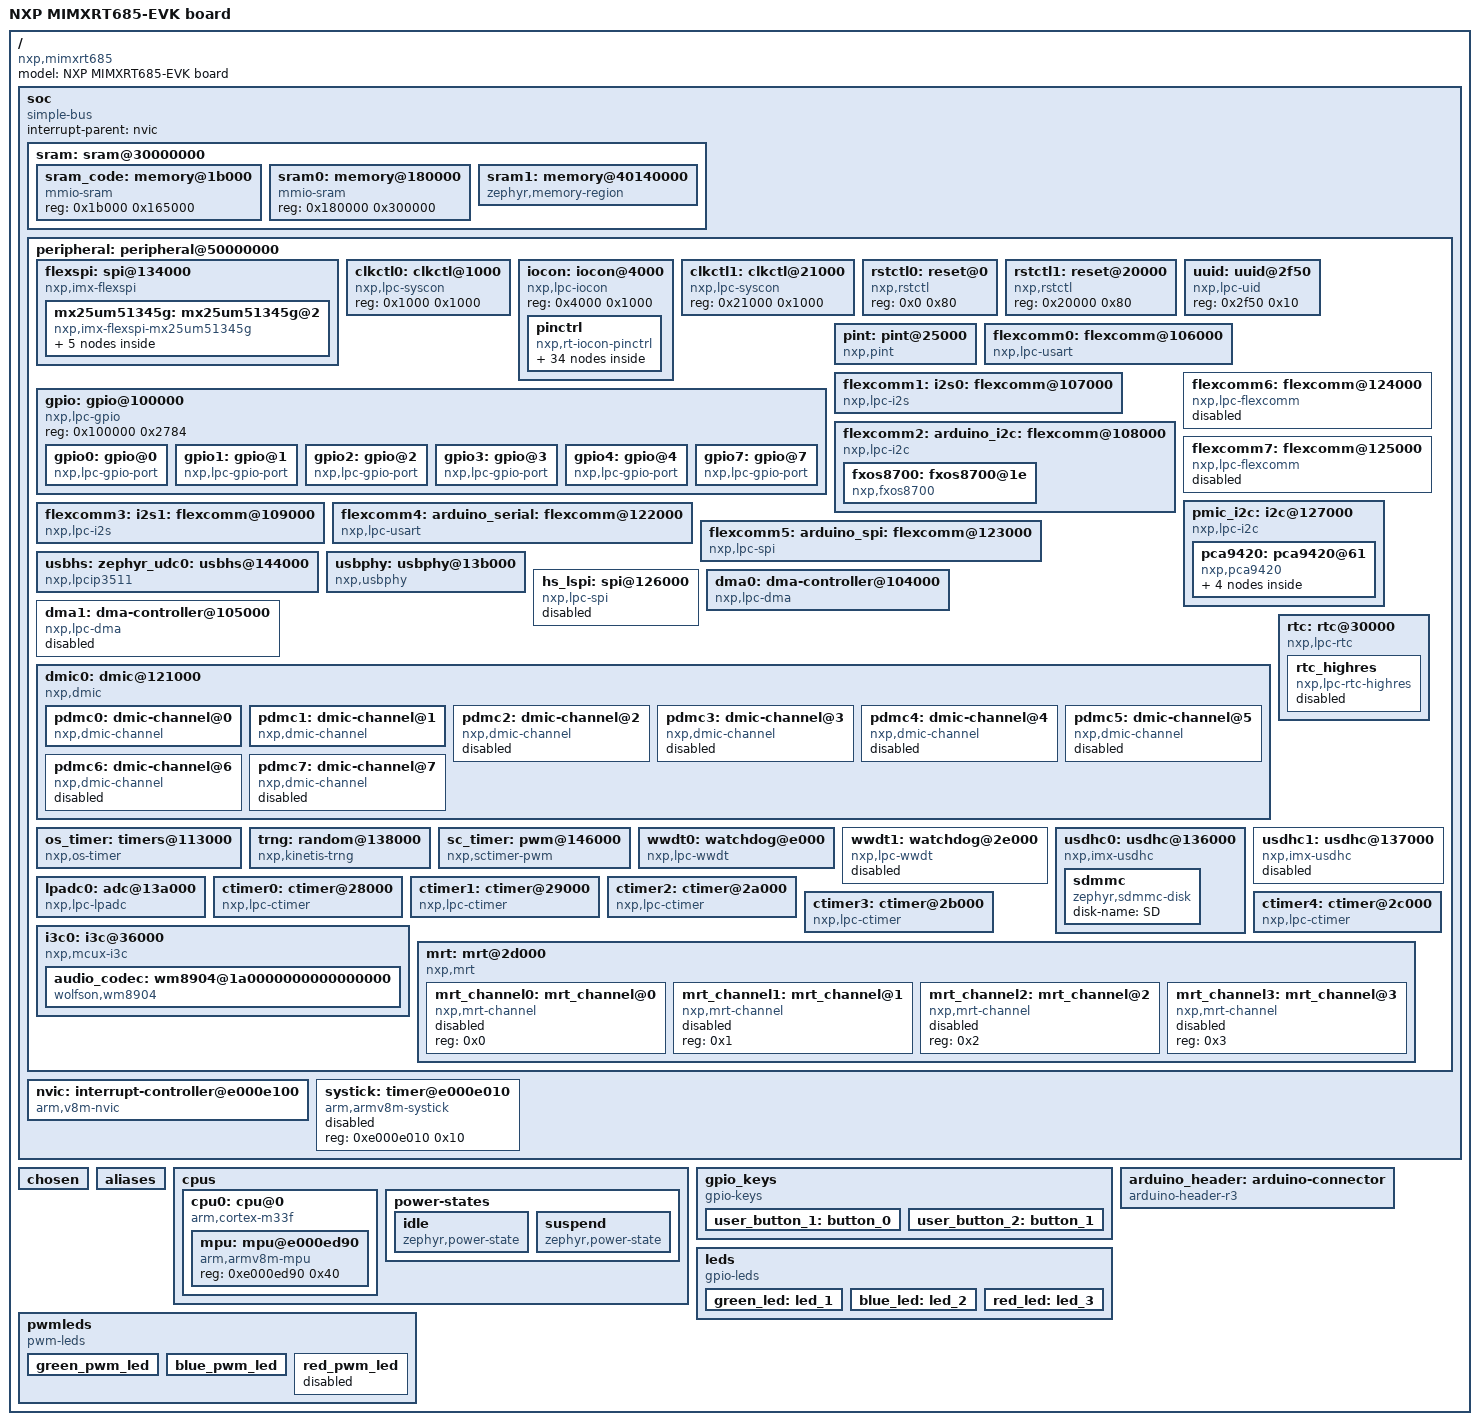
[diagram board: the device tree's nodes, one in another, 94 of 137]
/dts-v1/;

/ {
	#address-cells = < 0x1 >;
	#size-cells = < 0x1 >;
	model = "NXP MIMXRT685-EVK board";
	compatible = "nxp,mimxrt685";
	soc {
		#address-cells = < 0x1 >;
		#size-cells = < 0x1 >;
		compatible = "simple-bus";
		interrupt-parent = < &nvic >;
		ranges;
		sram: sram@30000000 {
			ranges = < 0x20000000 0x30000000 0x500000 0x0 0x10000000 0x500000 >;
			#address-cells = < 0x1 >;
			#size-cells = < 0x1 >;
			sram_code: memory@1b000 {
				compatible = "mmio-sram";
				reg = < 0x1b000 0x165000 >;
			};
			sram0: memory@180000 {
				compatible = "mmio-sram";
				reg = < 0x180000 0x300000 >;
			};
			sram1: memory@40140000 {
				compatible = "zephyr,memory-region", "mmio-sram";
				reg = < 0x40140000 0x4000 >;
				zephyr,memory-region = "SRAM1";
				zephyr,memory-attr = < 0x100000 >;
				status = "okay";
			};
		};
		peripheral: peripheral@50000000 {
			ranges = < 0x0 0x50000000 0x10000000 >;
			#address-cells = < 0x1 >;
			#size-cells = < 0x1 >;
			flexspi: spi@134000 {
				reg = < 0x134000 0x1000 >, < 0x18000000 0x8000000 >;
				compatible = "nxp,imx-flexspi";
				interrupts = < 0x2a 0x0 >;
				#address-cells = < 0x1 >;
				#size-cells = < 0x0 >;
				status = "okay";
				clocks = < &clkctl1 0xa00 >;
				pinctrl-0 = < &pinmux_flexspi >;
				pinctrl-names = "default";
				mx25um51345g: mx25um51345g@2 {
					compatible = "nxp,imx-flexspi-mx25um51345g";
					size = < 0x20000000 >;
					reg = < 0x2 >;
					spi-max-frequency = < 0xbebc200 >;
					status = "okay";
					jedec-id = [ C2 81 3A ];
					erase-block-size = < 0x1000 >;
					write-block-size = < 0x1 >;
					partitions {
						compatible = "fixed-partitions";
						#address-cells = < 0x1 >;
						#size-cells = < 0x1 >;
						boot_partition: partition@0 {
							label = "mcuboot";
							reg = < 0x0 0x20000 >;
						};
						slot0_partition: partition@20000 {
							label = "image-0";
							reg = < 0x20000 0x302000 >;
						};
						slot1_partition: partition@323000 {
							label = "image-1";
							reg = < 0x323000 0x300000 >;
						};
						storage_partition: partition@623000 {
							label = "storage";
							reg = < 0x623000 0x39de000 >;
						};
					};
				};
			};
			clkctl0: clkctl@1000 {
				compatible = "nxp,lpc-syscon";
				reg = < 0x1000 0x1000 >;
				#clock-cells = < 0x1 >;
				phandle = < 0xf >;
			};
			iocon: iocon@4000 {
				compatible = "nxp,lpc-iocon";
				reg = < 0x4000 0x1000 >;
				pinctrl: pinctrl {
					compatible = "nxp,rt-iocon-pinctrl";
					pinmux_flexcomm0_usart: pinmux_flexcomm0_usart {
						phandle = < 0x5 >;
						group0 {
							pinmux = < 0x200001 >;
							input-enable;
							slew-rate = "normal";
							drive-strength = "normal";
						};
						group1 {
							pinmux = < 0x100001 >;
							slew-rate = "normal";
							drive-strength = "normal";
							input-enable;
						};
					};
					pinmux_flexcomm1_i2s: pinmux_flexcomm1_i2s {
						phandle = < 0x7 >;
						group0 {
							pinmux = < 0x900001 >;
							input-enable;
							slew-rate = "normal";
							drive-strength = "high";
						};
					};
					pinmux_flexcomm2_i2c: pinmux_flexcomm2_i2c {
						phandle = < 0x8 >;
						group0 {
							pinmux = < 0x1100001 >, < 0x1200001 >;
							bias-pull-up;
							input-enable;
							slew-rate = "normal";
							drive-strength = "high";
							drive-open-drain;
						};
					};
					pinmux_flexcomm3_i2s: pinmux_flexcomm3_i2s {
						phandle = < 0xa >;
						group0 {
							pinmux = < 0x1700001 >, < 0x1600001 >, < 0x1500001 >, < 0x2a00001 >;
							input-enable;
							slew-rate = "normal";
							drive-strength = "high";
						};
					};
					pinmux_flexcomm4_usart: pinmux_flexcomm4_usart {
						phandle = < 0xb >;
						group0 {
							pinmux = < 0x1e00001 >;
							input-enable;
							slew-rate = "normal";
							drive-strength = "normal";
						};
						group1 {
							pinmux = < 0x1d00001 >;
							slew-rate = "normal";
							drive-strength = "normal";
						};
					};
					pinmux_flexcomm5_spi: pinmux_flexcomm5_spi {
						phandle = < 0xc >;
						group0 {
							pinmux = < 0x2300001 >, < 0x2400001 >, < 0x2500001 >, < 0x2600001 >;
							input-enable;
							slew-rate = "normal";
							drive-strength = "normal";
						};
					};
					pinmux_dmic0: pinmux_dmic0 {
						phandle = < 0x10 >;
						group0 {
							pinmux = < 0x5500001 >, < 0x5400001 >, < 0x5000001 >;
							slew-rate = "normal";
							drive-strength = "normal";
							input-enable;
						};
					};
					pinmux_flexspi: pinmux_flexspi {
						phandle = < 0x3 >;
						group0 {
							pinmux = < 0x2b00006 >, < 0x2c00006 >, < 0x2d00006 >, < 0x2e00006 >, < 0x3d00005 >, < 0x5100006 >, < 0x5200006 >, < 0x5300006 >, < 0x5600006 >, < 0x5700006 >;
							input-enable;
							slew-rate = "normal";
							drive-strength = "high";
						};
						group1 {
							pinmux = < 0x4c00000 >;
							slew-rate = "normal";
							drive-strength = "normal";
						};
					};
					pinmux_lpadc0: pinmux_lpadc0 {
						phandle = < 0x14 >;
						group0 {
							pinmux = < 0x500000 >, < 0x600000 >;
							slew-rate = "normal";
							drive-strength = "normal";
							nxp,analog-mode;
						};
					};
					pinmux_pmic_i2c: pinmux_pmic_i2c {
						phandle = < 0xd >;
						group0 {
							pinmux = < 0x10000000 >, < 0x10100000 >;
							bias-pull-up;
							input-enable;
							slew-rate = "normal";
							drive-strength = "normal";
							drive-open-drain;
						};
					};
					pinmux_sctimer: pinmux_sctimer {
						phandle = < 0x11 >;
						group0 {
							pinmux = < 0x1b00003 >, < 0xe00003 >, < 0x1a00003 >, < 0x1f00003 >;
							slew-rate = "normal";
							drive-strength = "normal";
						};
					};
					pinmux_usdhc: pinmux_usdhc {
						phandle = < 0x13 >;
						group0 {
							pinmux = < 0x3f00001 >, < 0x4000001 >, < 0x4100001 >, < 0x4200001 >, < 0x4300001 >, < 0x4900000 >;
							bias-pull-up;
							input-enable;
							slew-rate = "normal";
							drive-strength = "normal";
						};
						group1 {
							pinmux = < 0x3e00001 >;
							input-enable;
							slew-rate = "normal";
							drive-strength = "normal";
						};
						group2 {
							pinmux = < 0x4a00000 >, < 0x4400000 >;
							slew-rate = "normal";
							drive-strength = "normal";
						};
					};
					pinmux_i3c: pinmux_i3c {
						phandle = < 0x15 >;
						group0 {
							pinmux = < 0x5d00001 >, < 0x5e00001 >;
							input-enable;
							slew-rate = "slow";
							drive-strength = "high";
						};
						group1 {
							pinmux = < 0x5f00001 >;
							slew-rate = "normal";
							drive-strength = "normal";
						};
					};
					pinmux_ctimer2_pwm: pinmux_ctimer2_pwm {
						group0 {
							pinmux = < 0xe00004 >;
							slew-rate = "normal";
							drive-strength = "normal";
						};
					};
				};
			};
			clkctl1: clkctl@21000 {
				compatible = "nxp,lpc-syscon";
				reg = < 0x21000 0x1000 >;
				#clock-cells = < 0x1 >;
				phandle = < 0x2 >;
			};
			rstctl0: reset@0 {
				compatible = "nxp,rstctl";
				reg = < 0x0 0x80 >;
				#reset-cells = < 0x1 >;
			};
			rstctl1: reset@20000 {
				compatible = "nxp,rstctl";
				reg = < 0x20000 0x80 >;
				#reset-cells = < 0x1 >;
				phandle = < 0x4 >;
			};
			uuid: uuid@2f50 {
				compatible = "nxp,lpc-uid";
				reg = < 0x2f50 0x10 >;
			};
			gpio: gpio@100000 {
				compatible = "nxp,lpc-gpio";
				reg = < 0x100000 0x2784 >;
				#address-cells = < 0x1 >;
				#size-cells = < 0x0 >;
				gpio0: gpio@0 {
					compatible = "nxp,lpc-gpio-port";
					int-source = "pint";
					gpio-controller;
					#gpio-cells = < 0x2 >;
					reg = < 0x0 >;
					status = "okay";
					phandle = < 0x18 >;
				};
				gpio1: gpio@1 {
					compatible = "nxp,lpc-gpio-port";
					int-source = "pint";
					gpio-controller;
					#gpio-cells = < 0x2 >;
					reg = < 0x1 >;
					status = "okay";
					phandle = < 0x9 >;
				};
				gpio2: gpio@2 {
					compatible = "nxp,lpc-gpio-port";
					gpio-controller;
					#gpio-cells = < 0x2 >;
					reg = < 0x2 >;
					status = "okay";
					phandle = < 0x12 >;
				};
				gpio3: gpio@3 {
					compatible = "nxp,lpc-gpio-port";
					gpio-controller;
					#gpio-cells = < 0x2 >;
					reg = < 0x3 >;
				};
				gpio4: gpio@4 {
					compatible = "nxp,lpc-gpio-port";
					gpio-controller;
					#gpio-cells = < 0x2 >;
					reg = < 0x4 >;
				};
				gpio7: gpio@7 {
					compatible = "nxp,lpc-gpio-port";
					gpio-controller;
					#gpio-cells = < 0x2 >;
					reg = < 0x7 >;
				};
			};
			pint: pint@25000 {
				compatible = "nxp,pint";
				reg = < 0x25000 0x1000 >;
				interrupt-controller;
				#interrupt-cells = < 0x1 >;
				#address-cells = < 0x0 >;
				interrupts = < 0x4 0x2 >, < 0x5 0x2 >, < 0x6 0x2 >, < 0x7 0x2 >, < 0x23 0x2 >, < 0x24 0x2 >, < 0x25 0x2 >, < 0x26 0x2 >;
				num-lines = < 0x8 >;
				num-inputs = < 0x40 >;
			};
			flexcomm0: flexcomm@106000 {
				compatible = "nxp,lpc-usart";
				reg = < 0x106000 0x1000 >;
				interrupts = < 0xe 0x0 >;
				clocks = < &clkctl1 0x100 >;
				resets = < &rstctl1 0x8 >;
				status = "okay";
				current-speed = < 0x1c200 >;
				pinctrl-0 = < &pinmux_flexcomm0_usart >;
				pinctrl-names = "default";
				dmas = < &dma0 0x0 >, < &dma0 0x1 >;
				dma-names = "rx", "tx";
			};
			flexcomm1: i2s0: flexcomm@107000 {
				compatible = "nxp,lpc-i2s";
				reg = < 0x107000 0x1000 >;
				interrupts = < 0xf 0x0 >;
				clocks = < &clkctl1 0x101 >;
				resets = < &rstctl1 0x9 >;
				status = "okay";
				#address-cells = < 0x1 >;
				#size-cells = < 0x0 >;
				dmas = < &dma0 0x2 >;
				dma-names = "rx";
				pinctrl-0 = < &pinmux_flexcomm1_i2s >;
				pinctrl-names = "default";
			};
			flexcomm2: arduino_i2c: flexcomm@108000 {
				compatible = "nxp,lpc-i2c";
				reg = < 0x108000 0x1000 >;
				interrupts = < 0x10 0x0 >;
				clocks = < &clkctl1 0x102 >;
				resets = < &rstctl1 0xa >;
				status = "okay";
				pinctrl-0 = < &pinmux_flexcomm2_i2c >;
				pinctrl-names = "default";
				clock-frequency = < 0x61a80 >;
				#address-cells = < 0x1 >;
				#size-cells = < 0x0 >;
				fxos8700: fxos8700@1e {
					compatible = "nxp,fxos8700";
					reg = < 0x1e >;
					int1-gpios = < &gpio1 0x5 0x1 >;
					reset-gpios = < &gpio1 0x7 0x0 >;
				};
			};
			flexcomm3: i2s1: flexcomm@109000 {
				compatible = "nxp,lpc-i2s";
				reg = < 0x109000 0x1000 >;
				interrupts = < 0x11 0x0 >;
				clocks = < &clkctl1 0x103 >;
				resets = < &rstctl1 0xb >;
				status = "okay";
				#address-cells = < 0x1 >;
				#size-cells = < 0x0 >;
				dmas = < &dma0 0x7 >;
				dma-names = "tx";
				pinctrl-0 = < &pinmux_flexcomm3_i2s >;
				pinctrl-names = "default";
			};
			flexcomm4: arduino_serial: flexcomm@122000 {
				compatible = "nxp,lpc-usart";
				reg = < 0x122000 0x1000 >;
				interrupts = < 0x12 0x0 >;
				clocks = < &clkctl1 0x104 >;
				resets = < &rstctl1 0xc >;
				status = "okay";
				current-speed = < 0x1c200 >;
				pinctrl-0 = < &pinmux_flexcomm4_usart >;
				pinctrl-names = "default";
				dmas = < &dma0 0x8 >, < &dma0 0x9 >;
				dma-names = "rx", "tx";
			};
			flexcomm5: arduino_spi: flexcomm@123000 {
				compatible = "nxp,lpc-spi";
				reg = < 0x123000 0x1000 >;
				interrupts = < 0x13 0x0 >;
				clocks = < &clkctl1 0x105 >;
				resets = < &rstctl1 0xd >;
				status = "okay";
				#address-cells = < 0x1 >;
				#size-cells = < 0x0 >;
				dmas = < &dma0 0xa >, < &dma0 0xb >;
				dma-names = "rx", "tx";
				pinctrl-0 = < &pinmux_flexcomm5_spi >;
				pinctrl-names = "default";
			};
			flexcomm6: flexcomm@124000 {
				compatible = "nxp,lpc-flexcomm";
				reg = < 0x124000 0x1000 >;
				interrupts = < 0x2b 0x0 >;
				clocks = < &clkctl1 0x106 >;
				resets = < &rstctl1 0xe >;
				status = "disabled";
			};
			flexcomm7: flexcomm@125000 {
				compatible = "nxp,lpc-flexcomm";
				reg = < 0x125000 0x1000 >;
				interrupts = < 0x2c 0x0 >;
				clocks = < &clkctl1 0x107 >;
				resets = < &rstctl1 0xf >;
				status = "disabled";
			};
			pmic_i2c: i2c@127000 {
				compatible = "nxp,lpc-i2c";
				reg = < 0x127000 0x1000 >;
				interrupts = < 0x15 0x0 >;
				clocks = < &clkctl1 0x10f >;
				resets = < &rstctl1 0x17 >;
				status = "okay";
				clock-frequency = < 0x61a80 >;
				#address-cells = < 0x1 >;
				#size-cells = < 0x0 >;
				pinctrl-0 = < &pinmux_pmic_i2c >;
				pinctrl-names = "default";
				pca9420: pca9420@61 {
					compatible = "nxp,pca9420";
					reg = < 0x61 >;
					nxp,enable-modesel-pins;
					buck1: BUCK1 {
						regulator-boot-on;
					};
					buck2: BUCK2 {
						regulator-boot-on;
					};
					ldo1: LDO1 {
						regulator-boot-on;
					};
					ldo2: LDO2 {
						regulator-boot-on;
					};
				};
			};
			usbhs: zephyr_udc0: usbhs@144000 {
				compatible = "nxp,lpcip3511";
				reg = < 0x144000 0x1000 >;
				interrupts = < 0x32 0x1 >;
				num-bidir-endpoints = < 0x6 >;
				status = "okay";
				phy_handle = < &usbphy >;
			};
			usbphy: usbphy@13b000 {
				compatible = "nxp,usbphy";
				reg = < 0x13b000 0x1000 >;
				status = "okay";
				tx-d-cal = < 0xc >;
				tx-cal-45-dp-ohms = < 0x6 >;
				tx-cal-45-dm-ohms = < 0x6 >;
				phandle = < 0xe >;
			};
			hs_lspi: spi@126000 {
				compatible = "nxp,lpc-spi";
				reg = < 0x126000 0x1000 >;
				interrupts = < 0x14 0x0 >;
				clocks = < &clkctl1 0x10e >;
				resets = < &rstctl1 0x16 >;
				status = "disabled";
				#address-cells = < 0x1 >;
				#size-cells = < 0x0 >;
			};
			dma0: dma-controller@104000 {
				compatible = "nxp,lpc-dma";
				reg = < 0x104000 0x1000 >;
				interrupts = < 0x1 0x0 >;
				dma-channels = < 0x21 >;
				status = "okay";
				#dma-cells = < 0x1 >;
				phandle = < 0x6 >;
			};
			dma1: dma-controller@105000 {
				compatible = "nxp,lpc-dma";
				reg = < 0x105000 0x1000 >;
				interrupts = < 0x36 0x0 >;
				dma-channels = < 0x21 >;
				status = "disabled";
				#dma-cells = < 0x1 >;
			};
			dmic0: dmic@121000 {
				#address-cells = < 0x1 >;
				#size-cells = < 0x0 >;
				compatible = "nxp,dmic";
				reg = < 0x121000 0x1000 >;
				interrupts = < 0x19 0x0 >;
				status = "okay";
				clocks = < &clkctl0 0xa00 >;
				pinctrl-0 = < &pinmux_dmic0 >;
				pinctrl-names = "default";
				use2fs;
				pdmc0: dmic-channel@0 {
					compatible = "nxp,dmic-channel";
					reg = < 0x0 >;
					dmas = < &dma0 0x10 >;
					status = "okay";
					gainshift = < 0x3 >;
					dc-cutoff = "155hz";
					dc-gain = < 0x1 >;
				};
				pdmc1: dmic-channel@1 {
					compatible = "nxp,dmic-channel";
					reg = < 0x1 >;
					dmas = < &dma0 0x11 >;
					status = "okay";
					gainshift = < 0x3 >;
					dc-cutoff = "155hz";
					dc-gain = < 0x1 >;
				};
				pdmc2: dmic-channel@2 {
					compatible = "nxp,dmic-channel";
					reg = < 0x2 >;
					dmas = < &dma0 0x12 >;
					status = "disabled";
				};
				pdmc3: dmic-channel@3 {
					compatible = "nxp,dmic-channel";
					reg = < 0x3 >;
					dmas = < &dma0 0x13 >;
					status = "disabled";
				};
				pdmc4: dmic-channel@4 {
					compatible = "nxp,dmic-channel";
					reg = < 0x4 >;
					dmas = < &dma0 0x14 >;
					status = "disabled";
				};
				pdmc5: dmic-channel@5 {
					compatible = "nxp,dmic-channel";
					reg = < 0x5 >;
					dmas = < &dma0 0x15 >;
					status = "disabled";
				};
				pdmc6: dmic-channel@6 {
					compatible = "nxp,dmic-channel";
					reg = < 0x6 >;
					dmas = < &dma0 0x16 >;
					status = "disabled";
				};
				pdmc7: dmic-channel@7 {
					compatible = "nxp,dmic-channel";
					reg = < 0x7 >;
					dmas = < &dma0 0x17 >;
					status = "disabled";
				};
			};
			os_timer: timers@113000 {
				compatible = "nxp,os-timer";
				reg = < 0x113000 0x1000 >;
				interrupts = < 0x29 0x0 >;
				status = "okay";
				wakeup-source;
			};
			rtc: rtc@30000 {
				compatible = "nxp,lpc-rtc";
				reg = < 0x30000 0x1000 >;
				interrupts = < 0x20 0x0 >;
				status = "okay";
				rtc_highres: rtc_highres {
					compatible = "nxp,lpc-rtc-highres";
					status = "disabled";
				};
			};
			trng: random@138000 {
				compatible = "nxp,kinetis-trng";
				reg = < 0x138000 0x1000 >;
				status = "okay";
				interrupts = < 0x1f 0x0 >;
			};
			sc_timer: pwm@146000 {
				compatible = "nxp,sctimer-pwm";
				reg = < 0x146000 0x1000 >;
				interrupts = < 0xc 0x0 >;
				status = "okay";
				clocks = < &clkctl1 0x900 >;
				prescaler = < 0x8 >;
				#pwm-cells = < 0x3 >;
				pinctrl-0 = < &pinmux_sctimer >;
				pinctrl-names = "default";
				phandle = < 0x19 >;
			};
			wwdt0: watchdog@e000 {
				compatible = "nxp,lpc-wwdt";
				reg = < 0xe000 0x1000 >;
				interrupts = < 0x0 0x0 >;
				status = "okay";
				clk-divider = < 0x1 >;
			};
			wwdt1: watchdog@2e000 {
				compatible = "nxp,lpc-wwdt";
				reg = < 0x2e000 0x1000 >;
				interrupts = < 0x34 0x0 >;
				status = "disabled";
				clk-divider = < 0x1 >;
			};
			usdhc0: usdhc@136000 {
				compatible = "nxp,imx-usdhc";
				reg = < 0x136000 0x1000 >;
				status = "okay";
				interrupts = < 0x2d 0x0 >;
				clocks = < &clkctl1 0x200 >;
				max-current-330 = < 0x3fc >;
				max-current-180 = < 0x3fc >;
				max-bus-freq = < 0xc65d400 >;
				min-bus-freq = < 0x61a80 >;
				no-1-8-v;
				pwr-gpios = < &gpio2 0xa 0x0 >;
				cd-gpios = < &gpio2 0x9 0x1 >;
				pinctrl-0 = < &pinmux_usdhc >;
				pinctrl-names = "default";
				sdmmc {
					compatible = "zephyr,sdmmc-disk";
					disk-name = "SD";
					status = "okay";
				};
			};
			usdhc1: usdhc@137000 {
				compatible = "nxp,imx-usdhc";
				reg = < 0x137000 0x1000 >;
				status = "disabled";
				interrupts = < 0x2e 0x0 >;
				clocks = < &clkctl1 0x201 >;
				max-current-330 = < 0x3fc >;
				max-current-180 = < 0x3fc >;
				max-bus-freq = < 0xc65d400 >;
				min-bus-freq = < 0x61a80 >;
			};
			lpadc0: adc@13a000 {
				compatible = "nxp,lpc-lpadc";
				reg = < 0x13a000 0x304 >;
				interrupts = < 0x16 0x0 >;
				status = "okay";
				clk-divider = < 0x1 >;
				clk-source = < 0x0 >;
				voltage-ref = < 0x1 >;
				calibration-average = < 0x80 >;
				power-level = < 0x0 >;
				offset-value-a = < 0xa >;
				offset-value-b = < 0xa >;
				#io-channel-cells = < 0x1 >;
				clocks = < &clkctl1 0xf00 >;
				pinctrl-0 = < &pinmux_lpadc0 >;
				pinctrl-names = "default";
			};
			ctimer0: ctimer@28000 {
				compatible = "nxp,lpc-ctimer";
				reg = < 0x28000 0x1000 >;
				interrupts = < 0xa 0x0 >;
				status = "okay";
				clk-source = < 0x1 >;
				clocks = < &clkctl1 0x0 >;
				mode = < 0x0 >;
				input = < 0x0 >;
				prescale = < 0x0 >;
			};
			ctimer1: ctimer@29000 {
				compatible = "nxp,lpc-ctimer";
				reg = < 0x29000 0x1000 >;
				interrupts = < 0xb 0x0 >;
				status = "okay";
				clk-source = < 0x1 >;
				clocks = < &clkctl1 0x1 >;
				mode = < 0x0 >;
				input = < 0x0 >;
				prescale = < 0x0 >;
			};
			ctimer2: ctimer@2a000 {
				compatible = "nxp,lpc-ctimer";
				reg = < 0x2a000 0x1000 >;
				interrupts = < 0x27 0x0 >;
				status = "okay";
				clk-source = < 0x1 >;
				clocks = < &clkctl1 0x2 >;
				mode = < 0x0 >;
				input = < 0x0 >;
				prescale = < 0x0 >;
			};
			ctimer3: ctimer@2b000 {
				compatible = "nxp,lpc-ctimer";
				reg = < 0x2b000 0x1000 >;
				interrupts = < 0xd 0x0 >;
				status = "okay";
				clk-source = < 0x1 >;
				clocks = < &clkctl1 0x3 >;
				mode = < 0x0 >;
				input = < 0x0 >;
				prescale = < 0x0 >;
			};
			ctimer4: ctimer@2c000 {
				compatible = "nxp,lpc-ctimer";
				reg = < 0x2c000 0x1000 >;
				interrupts = < 0x28 0x0 >;
				status = "okay";
				clk-source = < 0x1 >;
				clocks = < &clkctl1 0x4 >;
				mode = < 0x0 >;
				input = < 0x0 >;
				prescale = < 0x0 >;
			};
			i3c0: i3c@36000 {
				compatible = "nxp,mcux-i3c";
				reg = < 0x36000 0x1000 >;
				interrupts = < 0x31 0x0 >;
				clocks = < &clkctl1 0x600 >;
				clk-divider = < 0x2 >;
				clk-divider-slow = < 0x1 >;
				clk-divider-tc = < 0x1 >;
				status = "okay";
				#address-cells = < 0x3 >;
				#size-cells = < 0x0 >;
				pinctrl-0 = < &pinmux_i3c >;
				pinctrl-names = "default";
				audio_codec: wm8904@1a0000000000000000 {
					compatible = "wolfson,wm8904";
					reg = < 0x1a 0x0 0x0 >;
					clock-source = "MCLK";
					clocks = < &clkctl0 0x1200 >;
					clock-names = "mclk";
				};
			};
			mrt: mrt@2d000 {
				compatible = "nxp,mrt";
				reg = < 0x2d000 0x100 >;
				interrupts = < 0x9 0x0 >;
				num-channels = < 0x4 >;
				num-bits = < 0x18 >;
				clocks = < &clkctl1 0xb00 >;
				resets = < &rstctl1 0x20008 >;
				#address-cells = < 0x1 >;
				#size-cells = < 0x0 >;
				mrt_channel0: mrt_channel@0 {
					compatible = "nxp,mrt-channel";
					reg = < 0x0 >;
					status = "disabled";
				};
				mrt_channel1: mrt_channel@1 {
					compatible = "nxp,mrt-channel";
					reg = < 0x1 >;
					status = "disabled";
				};
				mrt_channel2: mrt_channel@2 {
					compatible = "nxp,mrt-channel";
					reg = < 0x2 >;
					status = "disabled";
				};
				mrt_channel3: mrt_channel@3 {
					compatible = "nxp,mrt-channel";
					reg = < 0x3 >;
					status = "disabled";
				};
			};
		};
		nvic: interrupt-controller@e000e100 {
			#address-cells = < 0x1 >;
			compatible = "arm,v8m-nvic";
			reg = < 0xe000e100 0xc00 >;
			interrupt-controller;
			#interrupt-cells = < 0x2 >;
			arm,num-irq-priority-bits = < 0x3 >;
			phandle = < 0x1 >;
		};
		systick: timer@e000e010 {
			compatible = "arm,armv8m-systick";
			reg = < 0xe000e010 0x10 >;
			status = "disabled";
		};
	};
	chosen {
		zephyr,entropy = &trng;
		zephyr,flash-controller = &mx25um51345g;
		zephyr,flash = &mx25um51345g;
		zephyr,code-partition = &slot0_partition;
		zephyr,uart-mcumgr = &flexcomm0;
		zephyr,sram = &sram0;
		zephyr,console = &flexcomm0;
		zephyr,shell-uart = &flexcomm0;
	};
	aliases {
		sw0 = &user_button_1;
		sw1 = &user_button_2;
		led0 = &green_led;
		led1 = &blue_led;
		led2 = &red_led;
		usart-0 = &flexcomm0;
		pwm-0 = &sc_timer;
		pwm-led0 = &green_pwm_led;
		green-pwm-led = &green_pwm_led;
		blue-pwm-led = &blue_pwm_led;
		red-pwm-led = &red_pwm_led;
		watchdog0 = &wwdt0;
		magn0 = &fxos8700;
		accel0 = &fxos8700;
		sdhc0 = &usdhc0;
		dmic-dev = &dmic0;
		mcuboot-button0 = &user_button_1;
	};
	cpus {
		#address-cells = < 0x1 >;
		#size-cells = < 0x0 >;
		cpu0: cpu@0 {
			compatible = "arm,cortex-m33f";
			reg = < 0x0 >;
			cpu-power-states = < &idle &suspend >;
			#address-cells = < 0x1 >;
			#size-cells = < 0x1 >;
			mpu: mpu@e000ed90 {
				compatible = "arm,armv8m-mpu";
				reg = < 0xe000ed90 0x40 >;
			};
		};
		power-states {
			idle: idle {
				compatible = "zephyr,power-state";
				power-state-name = "runtime-idle";
				min-residency-us = < 0xa >;
				phandle = < 0x16 >;
			};
			suspend: suspend {
				compatible = "zephyr,power-state";
				power-state-name = "suspend-to-idle";
				min-residency-us = < 0x3e8 >;
				phandle = < 0x17 >;
			};
		};
	};
	gpio_keys {
		compatible = "gpio-keys";
		user_button_1: button_0 {
			label = "User SW1";
			gpios = < &gpio1 0x1 0x1 >;
			zephyr,code = < 0xb >;
			status = "okay";
		};
		user_button_2: button_1 {
			label = "User SW2";
			gpios = < &gpio0 0xa 0x1 >;
			zephyr,code = < 0x2 >;
			status = "okay";
		};
	};
	leds: leds {
		compatible = "gpio-leds";
		green_led: led_1 {
			gpios = < &gpio0 0xe 0x0 >;
			label = "User LED_GREEN";
			status = "okay";
		};
		blue_led: led_2 {
			gpios = < &gpio0 0x1a 0x0 >;
			label = "User LED_BLUE";
			status = "okay";
		};
		red_led: led_3 {
			gpios = < &gpio0 0x1f 0x0 >;
			label = "User LED_RED";
			status = "okay";
		};
	};
	pwmleds {
		compatible = "pwm-leds";
		green_pwm_led: green_pwm_led {
			pwms = < &sc_timer 0x0 0x1312d00 0x0 >;
			label = "Green PWM LED";
			status = "okay";
		};
		blue_pwm_led: blue_pwm_led {
			pwms = < &sc_timer 0x6 0x1312d00 0x0 >;
			label = "Blue PWM LED";
			status = "okay";
		};
		red_pwm_led: red_pwm_led {
			pwms = < &sc_timer 0x6 0x1312d00 0x0 >;
			label = "Red PWM LED";
			status = "disabled";
		};
	};
	arduino_header: arduino-connector {
		compatible = "arduino-header-r3";
		#gpio-cells = < 0x2 >;
		gpio-map-mask = < 0xffffffff 0xffffffc0 >;
		gpio-map-pass-thru = < 0x0 0x3f >;
		gpio-map = < 0x0 0x0 &gpio0 0x5 0x0 >, < 0x1 0x0 &gpio0 0x6 0x0 >, < 0x2 0x0 &gpio0 0x13 0x0 >, < 0x3 0x0 &gpio0 0x14 0x0 >, < 0x4 0x0 &gpio0 0x11 0x0 >, < 0x5 0x0 &gpio0 0x12 0x0 >, < 0x6 0x0 &gpio0 0x1e 0x0 >, < 0x7 0x0 &gpio0 0x1d 0x0 >, < 0x8 0x0 &gpio0 0x1c 0x0 >, < 0x9 0x0 &gpio0 0x1b 0x0 >, < 0xa 0x0 &gpio1 0x0 0x0 >, < 0xb 0x0 &gpio1 0xa 0x0 >, < 0xc 0x0 &gpio1 0x2 0x0 >, < 0xd 0x0 &gpio1 0x8 0x0 >, < 0xe 0x0 &gpio1 0x9 0x0 >, < 0xf 0x0 &gpio1 0x7 0x0 >, < 0x10 0x0 &gpio1 0x6 0x0 >, < 0x11 0x0 &gpio1 0x5 0x0 >, < 0x12 0x0 &gpio1 0x4 0x0 >, < 0x13 0x0 &gpio1 0x3 0x0 >, < 0x14 0x0 &gpio0 0x11 0x0 >, < 0x15 0x0 &gpio0 0x12 0x0 >;
	};
};
